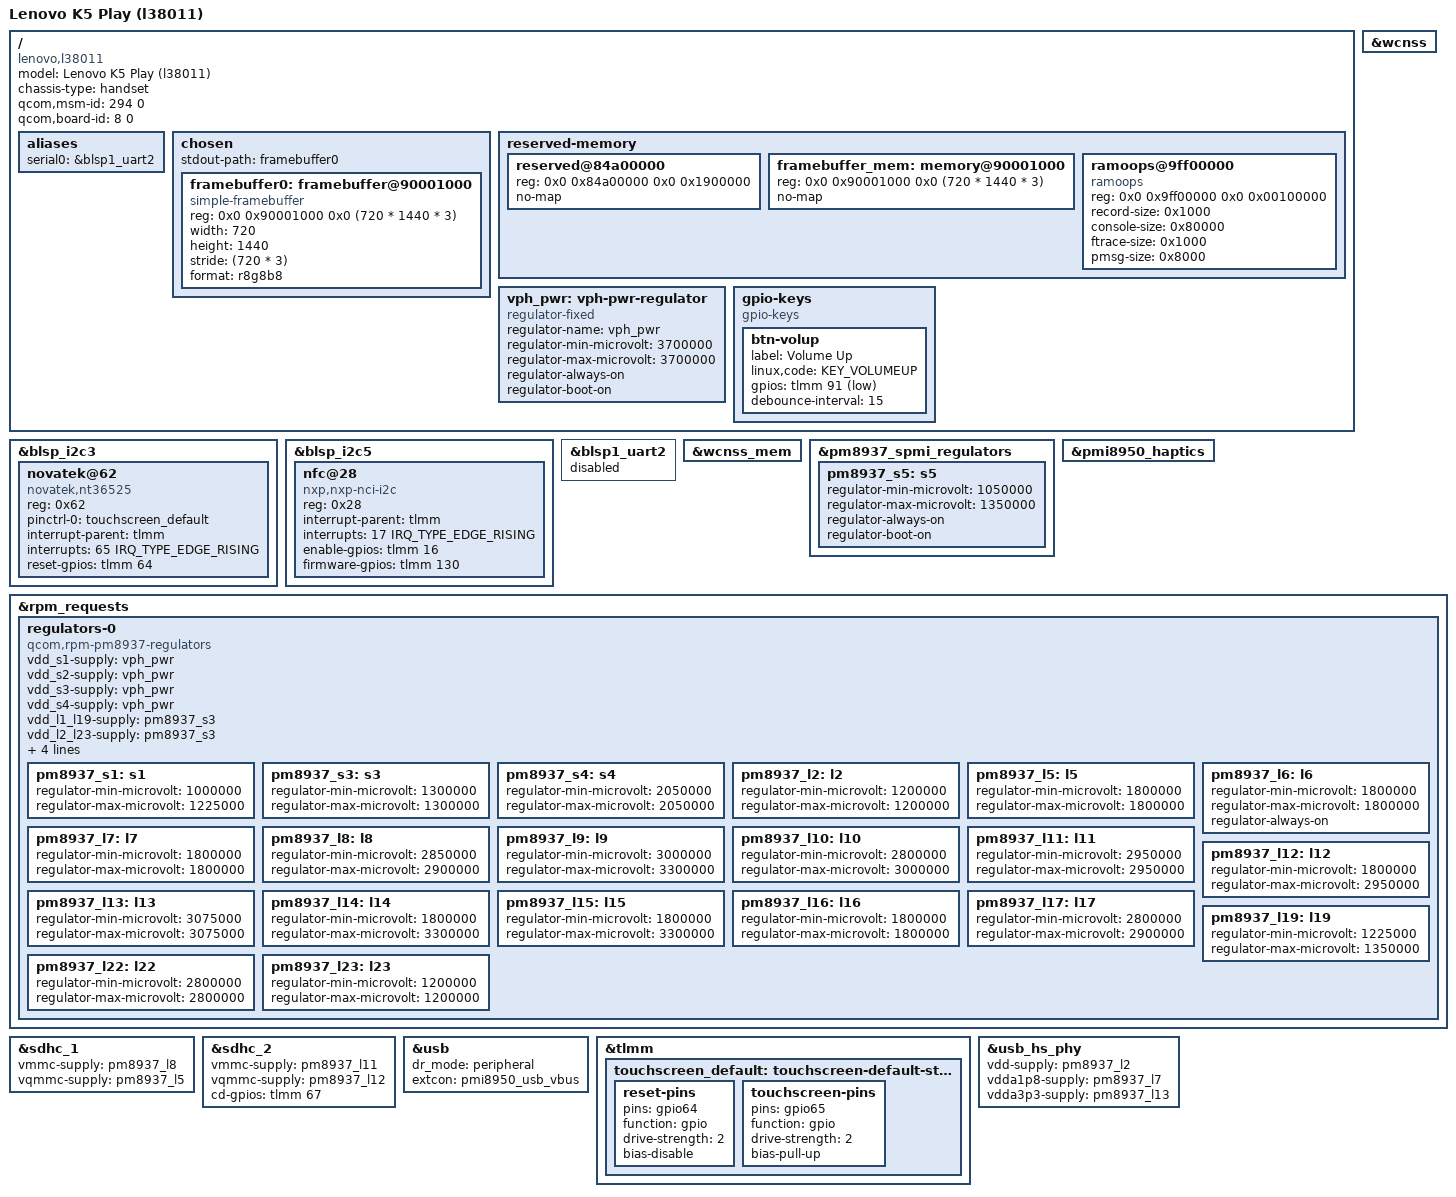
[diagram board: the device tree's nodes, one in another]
// SPDX-License-Identifier: BSD-3-Clause

/dts-v1/;

#include <dt-bindings/arm/qcom,ids.h>
#include <dt-bindings/gpio/gpio.h>
#include <dt-bindings/leds/common.h>
#include "msm8937.dtsi"
#include "pm8937.dtsi"
#include "pmi8950.dtsi"

/ {
	model = "Lenovo K5 Play (l38011)";
	compatible = "lenovo,l38011", "qcom,msm8937";
	chassis-type = "handset";

	qcom,msm-id = <294 0>;
	qcom,board-id = <8 0>;

	aliases {
		serial0 = &blsp1_uart2;
	};

	chosen {
		#address-cells = <2>;
		#size-cells = <2>;
		ranges;

		stdout-path = "framebuffer0";

		framebuffer0: framebuffer@90001000 {
			compatible = "simple-framebuffer";
			reg = <0x0 0x90001000 0x0 (720 * 1440 * 3)>;
			width = <720>;
			height = <1440>;
			stride = <(720 * 3)>;
			format = "r8g8b8";
		};
	};

	reserved-memory {
		/delete-node/ reserved@85b00000;

		/* QSEECOM */
		reserved@84a00000 {
			reg = <0x0 0x84a00000 0x0 0x1900000>;
			no-map;
		};

		framebuffer_mem: memory@90001000 {
			reg = <0x0 0x90001000 0x0 (720 * 1440 * 3)>;
			no-map;
		};
        
		ramoops@9ff00000 {
			compatible = "ramoops";
			reg = <0x0 0x9ff00000 0x0 0x00100000>;
			record-size = <0x1000>;
			console-size = <0x80000>;
			ftrace-size = <0x1000>;
			pmsg-size = <0x8000>;
		};
	};

	vph_pwr: vph-pwr-regulator {
		compatible = "regulator-fixed";
		regulator-name = "vph_pwr";
		regulator-min-microvolt = <3700000>;
		regulator-max-microvolt = <3700000>;
		regulator-always-on;
		regulator-boot-on;
	};

	gpio-keys {
		compatible = "gpio-keys";
		
		btn-volup {
			label = "Volume Up";
			linux,code = <KEY_VOLUMEUP>;
			gpios = <&tlmm 91 GPIO_ACTIVE_LOW>;
			debounce-interval = <15>;
		};
	};
};

&blsp_i2c3 {
	status = "okay";

	novatek@62 {
		compatible = "novatek,nt36525";
		reg = <0x62>;

		pinctrl-0 = <&touchscreen_default>;
		pinctrl-names = "default";

		interrupt-parent = <&tlmm>;
		interrupts = <65 IRQ_TYPE_EDGE_RISING>;

		reset-gpios = <&tlmm 64 GPIO_ACTIVE_HIGH>;
	};
};

&blsp_i2c5 {
	status = "okay";

	nfc@28 {
		compatible = "nxp,nxp-nci-i2c";

		reg = <0x28>;

		interrupt-parent = <&tlmm>;
		interrupts = <17 IRQ_TYPE_EDGE_RISING>;

		enable-gpios = <&tlmm 16 GPIO_ACTIVE_HIGH>;
		firmware-gpios = <&tlmm 130 GPIO_ACTIVE_HIGH>;
	};
};

&blsp1_uart2 {
	status = "disabled";
};

&wcnss {
	status = "okay";
};

&wcnss_mem {
	status = "okay";
};

&pm8937_spmi_regulators {
	/* PM8937 S5 + S6 = VDD_APC supply */
	pm8937_s5: s5 {
		regulator-min-microvolt = <1050000>;
		regulator-max-microvolt = <1350000>;
		regulator-always-on;
		regulator-boot-on;
	};
};

&pmi8950_haptics {
	status = "okay";
};

&rpm_requests {
	regulators-0 {
		compatible = "qcom,rpm-pm8937-regulators";

		vdd_s1-supply = <&vph_pwr>;
		vdd_s2-supply = <&vph_pwr>;
		vdd_s3-supply = <&vph_pwr>;
		vdd_s4-supply = <&vph_pwr>;

		vdd_l1_l19-supply = <&pm8937_s3>;
		vdd_l2_l23-supply = <&pm8937_s3>;
		vdd_l3-supply = <&pm8937_s3>;
		vdd_l4_l5_l6_l7_l16-supply = <&pm8937_s4>;
		vdd_l8_l11_l12_l17_l22-supply = <&vph_pwr>;
		vdd_l9_l10_l13_l14_l15_l18-supply = <&vph_pwr>;

		pm8937_s1: s1 {
			regulator-min-microvolt = <1000000>;
			regulator-max-microvolt = <1225000>;
		};

		/* S2: VDD_CX */

		pm8937_s3: s3 {
			regulator-min-microvolt = <1300000>;
			regulator-max-microvolt = <1300000>;
		};

		pm8937_s4: s4 {
			regulator-min-microvolt = <2050000>;
			regulator-max-microvolt = <2050000>;
		};

		pm8937_l2: l2 {
			regulator-min-microvolt = <1200000>;
			regulator-max-microvolt = <1200000>;
		};

		/* L3: VDD_MX */

		pm8937_l5: l5 {
			regulator-min-microvolt = <1800000>;
			regulator-max-microvolt = <1800000>;
		};

		pm8937_l6: l6 {
			regulator-min-microvolt = <1800000>;
			regulator-max-microvolt = <1800000>;
			regulator-always-on;
		};

		pm8937_l7: l7 {
			regulator-min-microvolt = <1800000>;
			regulator-max-microvolt = <1800000>;
		};

		pm8937_l8: l8 {
			regulator-min-microvolt = <2850000>;
			regulator-max-microvolt = <2900000>;
		};

		pm8937_l9: l9 {
			regulator-min-microvolt = <3000000>;
			regulator-max-microvolt = <3300000>;
		};

		pm8937_l10: l10 {
			regulator-min-microvolt = <2800000>;
			regulator-max-microvolt = <3000000>;
		};

		pm8937_l11: l11 {
			regulator-min-microvolt = <2950000>;
			regulator-max-microvolt = <2950000>;
		};

		pm8937_l12: l12 {
			regulator-min-microvolt = <1800000>;
			regulator-max-microvolt = <2950000>;
		};

		pm8937_l13: l13 {
			regulator-min-microvolt = <3075000>;
			regulator-max-microvolt = <3075000>;
		};

		pm8937_l14: l14 {
			regulator-min-microvolt = <1800000>;
			regulator-max-microvolt = <3300000>;
		};

		pm8937_l15: l15 {
			regulator-min-microvolt = <1800000>;
			regulator-max-microvolt = <3300000>;
		};

		pm8937_l16: l16 {
			regulator-min-microvolt = <1800000>;
			regulator-max-microvolt = <1800000>;
		};

		pm8937_l17: l17 {
			regulator-min-microvolt = <2800000>;
			regulator-max-microvolt = <2900000>;
		};

		pm8937_l19: l19 {
			regulator-min-microvolt = <1225000>;
			regulator-max-microvolt = <1350000>;
		};

		pm8937_l22: l22 {
			regulator-min-microvolt = <2800000>;
			regulator-max-microvolt = <2800000>;
		};

		pm8937_l23: l23 {
			regulator-min-microvolt = <1200000>;
			regulator-max-microvolt = <1200000>;
		};
	};
};

/* eMMC */
&sdhc_1 {
	vmmc-supply = <&pm8937_l8>;
	vqmmc-supply = <&pm8937_l5>;
	status = "okay";
};

/* SD Card */
&sdhc_2 {
	vmmc-supply = <&pm8937_l11>;
	vqmmc-supply = <&pm8937_l12>;

	cd-gpios = <&tlmm 67 GPIO_ACTIVE_HIGH>;

	status = "okay";
};

&usb {
	dr_mode = "peripheral";
	extcon = <&pmi8950_usb_vbus>;
	status = "okay";
};

&tlmm {
	touchscreen_default: touchscreen-default-state {
		reset-pins {
			pins = "gpio64";
			function = "gpio";
			drive-strength = <2>;
			bias-disable;
		};

		touchscreen-pins {
			pins = "gpio65";
			function = "gpio";
			drive-strength = <2>;
			bias-pull-up;
		};
	};
};

&usb_hs_phy {
	vdd-supply = <&pm8937_l2>;
	vdda1p8-supply = <&pm8937_l7>;
	vdda3p3-supply = <&pm8937_l13>;
	status = "okay";
};
